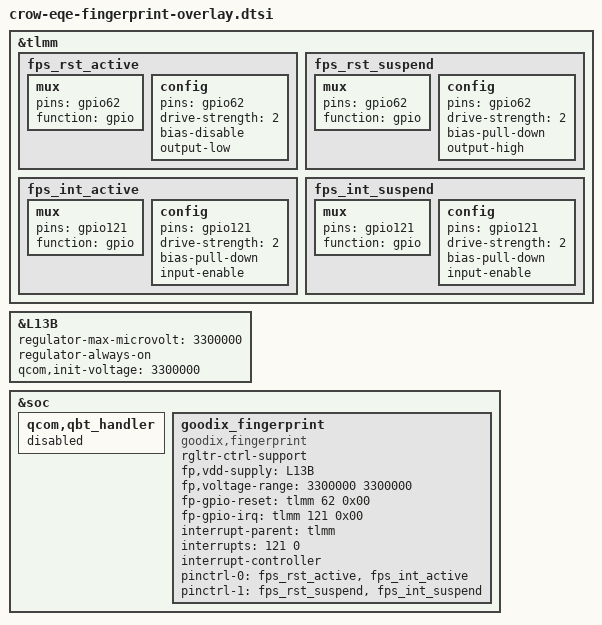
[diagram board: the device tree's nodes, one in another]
/* Copyright (c) 2023, The Linux Foundation. All rights reserved.
 *
 * This program is free software; you can redistribute it and/or modify
 * it under the terms of the GNU General Public License version 2 and
 * only version 2 as published by the Free Software Foundation.
 *
 * This program is distributed in the hope that it will be useful,
 * but WITHOUT ANY WARRANTY; without even the implied warranty of
 * MERCHANTABILITY or FITNESS FOR A PARTICULAR PURPOSE.  See the
 * GNU General Public License for more details.
 */

&tlmm {
	fps_rst_active: fps_rst_active {
		/* active state */
		mux {
			pins = "gpio62";
			function = "gpio";
		};

		config {
			pins = "gpio62";
			drive-strength = <2>; /* 2 MA */
			bias-disable;
			output-low;
		};
	};

	fps_rst_suspend: fps_rst_suspend {
		/* sleep state */
		mux {
			pins = "gpio62";
			function = "gpio";
		};

		config {
			pins = "gpio62";
			drive-strength = <2>; /* 2 MA */
			bias-pull-down; /* pull down */
			output-high;
		};
	};

	fps_int_active: fps_int_active {
		/* active state */
		mux {
			pins = "gpio121";
			function = "gpio";
		};

		config {
			pins = "gpio121";
			drive-strength = <2>; /* 2 MA */
			bias-pull-down; /* pull down */
			input-enable;
		};
	};

	fps_int_suspend: fps_int_suspend {
		/* sleep state */
		mux {
			pins = "gpio121";
			function = "gpio";
		};

		config {
			pins = "gpio121";
			drive-strength = <2>; /* 2 MA */
			bias-pull-down; /* pull down */
			input-enable;
		};
	};
};

&L13B {
	regulator-max-microvolt = <3300000>;
	regulator-always-on;
	qcom,init-voltage = <3300000>;
	status = "ok";
};

&soc {
	qcom,qbt_handler {
		status = "disabled";
	};
	goodix_fingerprint {
		compatible = "goodix,fingerprint";
		status = "ok";
		rgltr-ctrl-support;
		fp,vdd-supply = <&L13B>;
		fp,voltage-range = <3300000 3300000>;
		fp-gpio-reset = <&tlmm 62 0x00>;
		fp-gpio-irq = <&tlmm 121 0x00>;
		interrupt-parent = <&tlmm>;
		interrupts = <121 0>;
		interrupt-controller;
		pinctrl-names = "default", "suspend";
		pinctrl-0 = <&fps_rst_active &fps_int_active>;
		pinctrl-1 = <&fps_rst_suspend &fps_int_suspend>;
	};
};
